# STM32F3x4 register map
File version: 1.8
CPU: CM4 r1p0, little endian, MPU, FPU, 4 interrupt priority bits
Registers are 32-bit, read-write, reset 0x0 unless marked. A register's access mark holds for its fields unless they carry their own. Offsets are from the block's base; [hi:lo] are bit positions; {n}, {i} and the like mark numbered series; 'fields as' and 'values as' point back to an identical list.

## SYSCFG — System configuration controller
Base 0x40010000
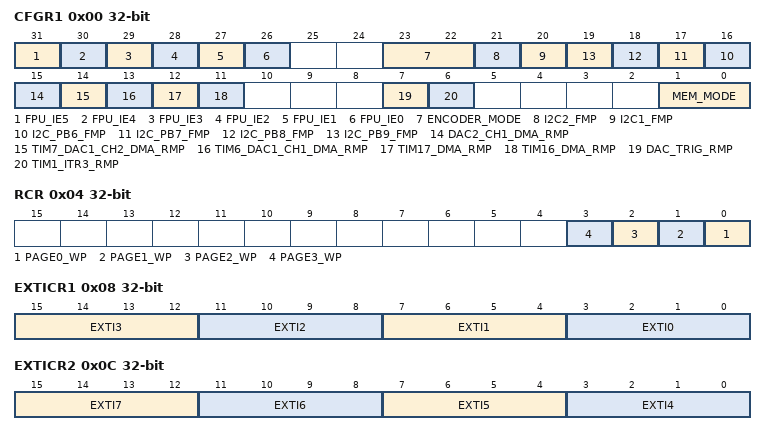
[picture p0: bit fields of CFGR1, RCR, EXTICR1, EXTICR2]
0x00 CFGR1 — configuration register 1
  [31] FPU_IE5 — Inexact interrupt enable
    0=Disabled (Inexact interrupt disable); 1=Enabled (Inexact interrupt enable)
  [30] FPU_IE4 — Input denormal interrupt enable
    0=Disabled (Input denormal interrupt disable); 1=Enabled (Input denormal interrupt enable)
  [29] FPU_IE3 — Overflow interrupt enable
    0=Disabled (Overflow interrupt disable); 1=Enabled (Overflow interrupt enable)
  [28] FPU_IE2 — Underflow interrupt enable
    0=Disabled (Underflow interrupt disable); 1=Enabled (Underflow interrupt enable)
  [27] FPU_IE1 — Devide-by-zero interrupt enable
    0=Disabled (Devide-by-zero interrupt disable); 1=Enabled (Devide-by-zero interrupt enable)
  [26] FPU_IE0 — Invalid operation interrupt enable
    0=Disabled (Invalid operation interrupt disable); 1=Enabled (Invalid operation interrupt enable)
  [23:22] ENCODER_MODE
    0=NoRedirection; 1=MapTim2Tim15 (TIM2 IC1 and TIM2 IC2 are connected to TIM15 IC1 and TIM15 IC2 respectively); 2=MapTim3Tim15 (TIM3 IC1 and TIM3 IC2 are connected to TIM15 IC1 and TIM15 IC2 respectively)
  [21] I2C2_FMP — I2C2 Fast Mode Plus
    0=Standard (FM+ mode is controlled by I2C_Pxx_FMP bits only); 1=FMP (FM+ mode is enabled on all I2C2 pins selected through selection through IOPORT control registers AF selection bits)
  [20] I2C1_FMP — I2C1 Fast Mode Plus
    0=Standard (FM+ mode is controlled by I2C_Pxx_FMP bits only); 1=FMP (FM+ mode is enabled on all I2C1 pins selected through selection through IOPORT control registers AF selection bits)
  [n+10] I2C_PB{n}_FMP (n=6..9) — Fast Mode Plus (FM+) driving capability activation bits.
    0=Standard (PB{n} pin operate in standard mode); 1=FMP (I2C FM+ mode enabled on PB{n} and the Speed control is bypassed)
  [15] DAC2_CH1_DMA_RMP — DAC2 channel1 DMA remap
    0=NotRemapped; 1=Remapped (DAC2_CH1 DMA requests mapped on DMA1 channel 5)
  [14] TIM7_DAC1_CH2_DMA_RMP — TIM7 and DAC2 DMA request remapping bit
    0=NotRemapped; 1=Remapped (TIM7_UP and DAC_CH2 DMA requests mapped on DMA1 channel 4)
  [13] TIM6_DAC1_CH1_DMA_RMP — TIM6 and DAC1 DMA request remapping bit
    0=NotRemapped (TIM6_UP and DAC_CH1 DMA requests mapped on DMA2 channel 3); 1=Remapped (TIM6_UP and DAC_CH1 DMA requests mapped on DMA1 channel 3)
  [12] TIM17_DMA_RMP — TIM17 DMA request remapping bit
    0=NotRemapped (TIM17_CH1 and TIM17_UP DMA requests mapped on DMA channel 1); 1=Remapped (TIM17_CH1 and TIM17_UP DMA requests mapped on DMA channel 2)
  [11] TIM16_DMA_RMP — TIM16 DMA request remapping bit
    0=NotRemapped (TIM16_CH1 and TIM16_UP DMA requests mapped on DMA channel 3); 1=Remapped (TIM16_CH1 and TIM16_UP DMA requests mapped on DMA channel 4)
  [7] DAC_TRIG_RMP — DAC trigger remap (when TSEL = 001)
    0=NotRemapped; 1=Remapped (DAC trigger is TIM3_TRGO)
  [6] TIM1_ITR3_RMP — Timer 1 ITR3 selection
    0=NotRemapped; 1=Remapped (TIM1_ITR3 = TIM17_OC)
  [1:0] MEM_MODE — Memory mapping selection bits
    0=Main Flash memory mapped at 0x0000_0000; 1=System Flash memory mapped at 0x0000_0000; 2=MainFlash2 (Main Flash memory mapped at 0x0000_0000); 3=SRAM (Embedded SRAM mapped at 0x0000_0000)
0x04 RCR — CCM SRAM protection register
  [all] fields
    0=Disabled (Write protection of pagex is disabled); 1=Enabled (Write protection of pagex is enabled)
  [n] PAGE{n}_WP (n=0..3) — CCM SRAM page write protection bit
0x08 EXTICR1 — external interrupt configuration register 1
  [15:12] EXTI3 — EXTI 3 configuration bits
    0=PA (Select PAx as the source input for the EXTIx external interrupt); 1=PB (Select PBx as the source input for the EXTIx external interrupt); 2=PC (Select PCx as the source input for the EXTIx external interrupt); 3=PD (Select PDx as the source input for the EXTIx external interrupt); 4=PE (Select PEx as the source input for the EXTIx external interrupt)
  [11:8] EXTI2 — EXTI 2 configuration bits
    0=PA (Select PAx as the source input for the EXTIx external interrupt); 1=PB (Select PBx as the source input for the EXTIx external interrupt); 2=PC (Select PCx as the source input for the EXTIx external interrupt); 3=PD (Select PDx as the source input for the EXTIx external interrupt); 4=PE (Select PEx as the source input for the EXTIx external interrupt); 5=PF (Select PFx as the source input for the EXTIx external interrupt)
  [7:4] EXTI1 — EXTI 1 configuration bits
    values as EXTI2
  [3:0] EXTI0 — EXTI 0 configuration bits
    values as EXTI2
0x0C EXTICR2 — external interrupt configuration register 2
  [15:12] EXTI7 — EXTI 7 configuration bits
    values as EXTICR1.EXTI3
  [11:8] EXTI6 — EXTI 6 configuration bits
    values as EXTICR1.EXTI2
  [7:4] EXTI5 — EXTI 5 configuration bits
    values as EXTICR1.EXTI2
  [3:0] EXTI4 — EXTI 4 configuration bits
    values as EXTICR1.EXTI2
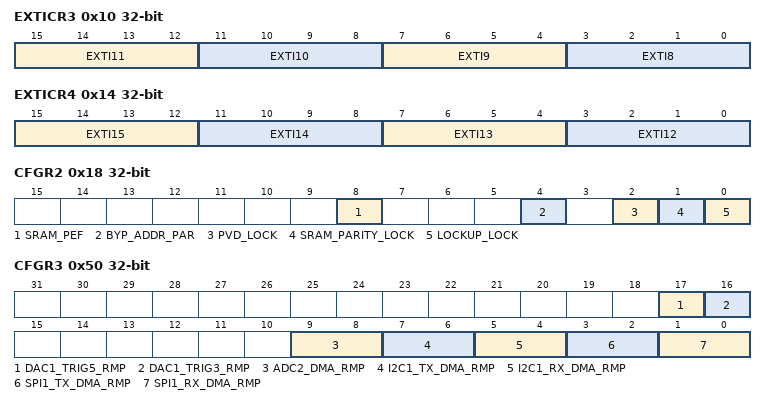
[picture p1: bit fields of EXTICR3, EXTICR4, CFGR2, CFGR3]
0x10 EXTICR3 — external interrupt configuration register 3
  [15:12] EXTI11 — EXTI 11 configuration bits
    values as EXTICR1.EXTI3
  [11:8] EXTI10 — EXTI 10 configuration bits
    values as EXTICR1.EXTI2
  [7:4] EXTI9 — EXTI 9 configuration bits
    values as EXTICR1.EXTI2
  [3:0] EXTI8 — EXTI 8 configuration bits
    values as EXTICR1.EXTI3
0x14 EXTICR4 — external interrupt configuration register 4
  [15:12] EXTI15 — EXTI 15 configuration bits
    values as EXTICR1.EXTI2
  [11:8] EXTI14 — EXTI 14 configuration bits
    values as EXTICR1.EXTI2
  [7:4] EXTI13 — EXTI 13 configuration bits
    values as EXTICR1.EXTI2
  [3:0] EXTI12 — EXTI 12 configuration bits
    values as EXTICR1.EXTI3
0x18 CFGR2 — configuration register 2
  [8] SRAM_PEF — SRAM parity flag
    on read: 0=NoParityError (No SRAM parity error detected); 1=ParityErrorDetected (SRAM parity error detected) | on write: 1=Clear SRAM parity error flag
  [4] BYP_ADDR_PAR — Bypass address bit 29 in parity calculation
    0=NoBypass (The ramload operation is performed taking into consideration bit 29 of the address when the parity is calculated); 1=Bypass (The ramload operation is performed without taking into consideration bit 29 of the address when the parity is calculated)
  [2] PVD_LOCK — PVD lock enable bit
    0=Disconnected (PVD interrupt disconnected from TIM15/16/17 Break input); 1=Connected (PVD interrupt connected to TIM15/16/17 Break input)
  [1] SRAM_PARITY_LOCK — SRAM parity lock bit
    0=Disconnected (SRAM parity error signal disconnected from TIM1/15/16/17 and HRTIM1 SYSFLT Break inputs); 1=Connected (SRAM parity error signal connected to TIM1/15/16/17 and HRTIM1 SYSFLT Break inputs)
  [0] LOCKUP_LOCK — Cortex-M0 LOCKUP bit enable bit
    0=Disconnected (Cortex-M4 LOCKUP output disconnected from TIM1/15/16/17 Break inputs and HRTIM1 SYSFLT.); 1=Connected (Cortex-M4 LOCKUP output connected to TIM1/15/16/17 and HRTIM1 SYSFLT Break inputs)
0x50 CFGR3 — configuration register 3
  [17] DAC1_TRIG5_RMP — DAC1_CH1 / DAC1_CH2 Trigger remap
    0=NotRemapped; 1=Remapped (DAC trigger is HRTIM1_DAC1_TRIG2)
  [16] DAC1_TRIG3_RMP — DAC1_CH1 / DAC1_CH2 Trigger remap
    0=Tim15 (DAC trigger is TIM15_TRGO); 1=HrTim1 (DAC trigger is HRTIM1_DAC1_TRIG1)
  [9:8] ADC2_DMA_RMP — ADC2 DMA remapping bit
    0=MapDma2 (ADC2 mapped on DMA2); 2=MapDma1Ch2 (ADC2 mapped on DMA1 channel 2); 3=MapDma1Ch4 (ADC2 mapped on DMA1 channel 4)
  [7:6] I2C1_TX_DMA_RMP — I2C1_TX DMA remapping bit
    0=MapDma1Ch6 (I2C1_TX mapped on DMA1 CH6); 1=MapDma1Ch2 (I2C1_TX mapped on DMA1 CH2); 2=MapDma1Ch4 (I2C1_TX mapped on DMA1 CH4)
  [5:4] I2C1_RX_DMA_RMP — I2C1_RX DMA remapping bit
    0=MapDma1Ch7 (I2C1_RX mapped on DMA1 CH7); 1=MapDma1Ch3 (I2C1_RX mapped on DMA1 CH3); 2=MapDma1Ch5 (I2C1_RX mapped on DMA1 CH5)
  [3:2] SPI1_TX_DMA_RMP — SPI1_TX DMA remapping bit
    0=MapDma1Ch3 (SPI1_TX mapped on DMA1 CH3); 1=MapDma1Ch5 (SPI1_TX mapped on DMA1 CH5); 2=MapDma1Ch7 (SPI1_TX mapped on DMA1 CH7)
  [1:0] SPI1_RX_DMA_RMP — SPI1_RX DMA remapping bit
    0=MapDma1Ch3 (SPI1_RX mapped on DMA1 CH2); 1=MapDma1Ch5 (SPI1_RX mapped on DMA1 CH4); 2=MapDma1Ch7 (SPI1_RX mapped on DMA1 CH6)
